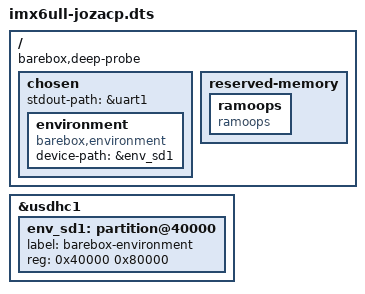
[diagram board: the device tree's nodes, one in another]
// SPDX-License-Identifier: GPL-2.0-or-later
/dts-v1/;

#include "imx6ull-jozacp.dtsi"

/ {
	barebox,deep-probe;

	chosen {
		stdout-path = &uart1;

		environment {
			compatible = "barebox,environment";
			device-path = &env_sd1;
		};
	};

	reserved-memory {
		#address-cells = <1>;
		#size-cells = <1>;
		ranges;

		/* Address will be determined by the bootloader */
		ramoops {
			compatible = "ramoops";
		};
	};
};

&usdhc1 {
	#address-cells = <1>;
	#size-cells = <1>;

	env_sd1: partition@40000 {
		label = "barebox-environment";
		reg = <0x40000 0x80000>;
	};
};
